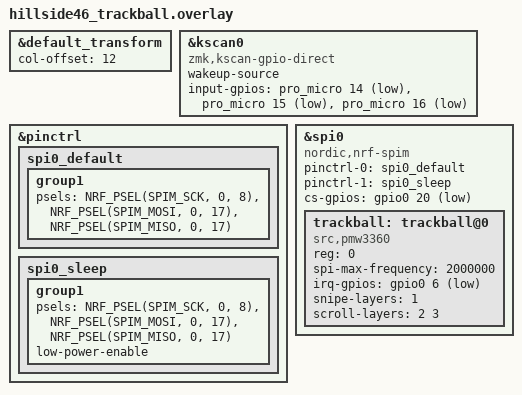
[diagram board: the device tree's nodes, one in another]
/*
 * Copyright (c) 2021-2022 The ZMK Contributors
 *
 * SPDX-License-Identifier: MIT
 */

#include "hillside46.dtsi" 

&default_transform {
    col-offset = <12>;
};

&kscan0 {
        compatible = "zmk,kscan-gpio-direct";
        wakeup-source;
        input-gpios
            = <&pro_micro 14 (GPIO_ACTIVE_LOW | GPIO_PULL_UP)>
            , <&pro_micro 15 (GPIO_ACTIVE_LOW | GPIO_PULL_UP)>
            , <&pro_micro 16 (GPIO_ACTIVE_LOW | GPIO_PULL_UP)>
            ;
    };

&pinctrl {
    spi0_default: spi0_default {
        group1 {
            psels = <NRF_PSEL(SPIM_SCK, 0, 8)>,
                <NRF_PSEL(SPIM_MOSI, 0, 17)>,
                <NRF_PSEL(SPIM_MISO, 0, 17)>;
        };
    };

    spi0_sleep: spi0_sleep {
        group1 {
            psels = <NRF_PSEL(SPIM_SCK, 0, 8)>,
                <NRF_PSEL(SPIM_MOSI, 0, 17)>,
                <NRF_PSEL(SPIM_MISO, 0, 17)>;
            low-power-enable;
        };
    };
};

&spi0 {
    status = "okay";
    compatible = "nordic,nrf-spim";
    pinctrl-0 = <&spi0_default>;
    pinctrl-1 = <&spi0_sleep>;
    pinctrl-names = "default", "sleep";
    cs-gpios = <&gpio0 20 GPIO_ACTIVE_LOW>;

    trackball: trackball@0 {
        status = "okay";
        compatible = "src,pmw3360";
        reg = <0>;
        spi-max-frequency = <2000000>;
        irq-gpios = <&gpio0 6 (GPIO_ACTIVE_LOW | GPIO_PULL_UP)>;

        /*   optional features   */
        snipe-layers = <1>;
        scroll-layers = <2 3>;
        // automouse-layer = <4>;
    };
};
